# R7KA8D2AD register map
Vendor: Renesas Electronics Corporation; Series: RA8; File version: 1.10.02
CPU: CM85 r0p2, little endian, MPU, FPU, VTOR, 4 interrupt priority bits, 96 interrupts
Registers are 32-bit, read-write, reset 0x0 unless marked. A register's access mark holds for its fields unless they carry their own. Offsets are from the block's base; [hi:lo] are bit positions; {n}, {i} and the like mark numbered series; 'fields as' and 'values as' point back to an identical list.

## PORT0 — Pmn Pin FunctionPort 0 Control RegistersPmn Pin Function Control Register
Base 0x40400000
Same registers: PORT5 0x404000A0, PORT6 0x404000C0, PORT7 0x404000E0, PORT8 0x40400100, PORT9 0x40400120, PORTA 0x40400140, PORTB 0x40400160, PORTC 0x40400180, PORTD 0x404001A0, PORT0_NS 0x50400000, PORT5_NS 0x504000A0, PORT6_NS 0x504000C0, PORT7_NS 0x504000E0, PORT8_NS 0x50400100, PORT9_NS 0x50400120, PORTA_NS 0x50400140, PORTB_NS 0x50400160, PORTC_NS 0x50400180, PORTD_NS 0x504001A0
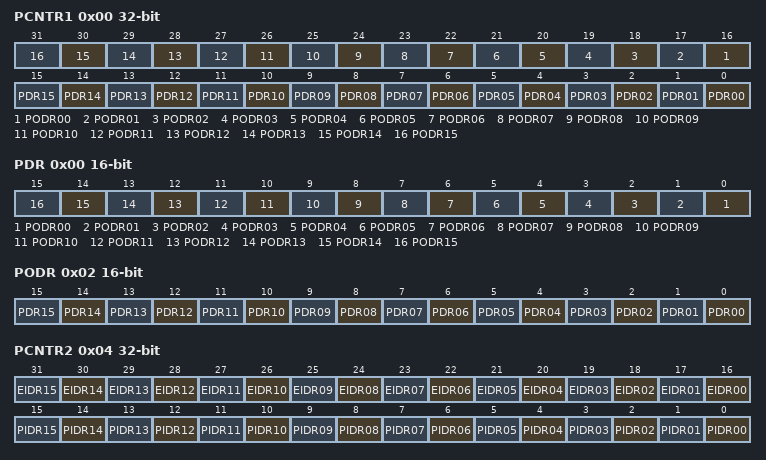
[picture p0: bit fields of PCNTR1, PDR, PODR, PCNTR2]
0x00 PCNTR1 — Port Control Register 1
  [n+16] PODR{n:02} (n=0..15) — Pmn Output Data
    0=Low output; 1=High output
  [n] PDR{n:02} (n=0..15) — Pmn Direction
    0=Input (functions as an input pin); 1=Output (functions as an output pin)
0x00 PDR 16-bit (alternate view of PCNTR1) — Port Control Register 1
  [all] fields
    0=Low output; 1=High output
  [n] PODR{n:02} (n=0..15) — Pmn Output Data
0x02 PODR 16-bit (alternate view of PCNTR1) — Port Control Register 1
  [all] fields
    values as PCNTR1.PDR00
  [n] PDR{n:02} (n=0..15) — Pmn Direction
0x04 PCNTR2 ro (reset mask 0xFFFF0000) — Port Control Register 2
  [n+16] EIDR{n:02} (n=0..15) — Port Event Input Data
    0=Low input; 1=High input
  [n] PIDR{n:02} (n=0..15) — Pmn State
    0=Low level; 1=High level
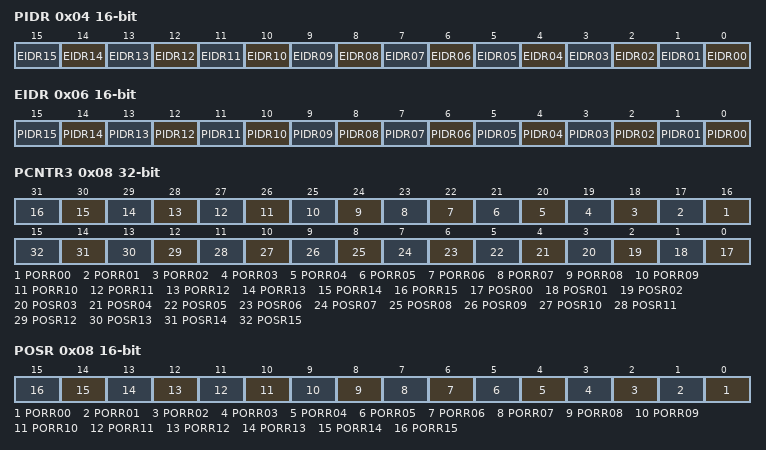
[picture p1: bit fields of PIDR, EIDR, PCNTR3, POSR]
0x04 PIDR 16-bit ro (alternate view of PCNTR2) — Port Control Register 2
  [all] fields
    0=Low input; 1=High input
  [n] EIDR{n:02} (n=0..15) — Port Event Input Data
0x06 EIDR 16-bit ro reset not defined (alternate view of PCNTR2) — Port Control Register 2
  [all] fields
    0=Low level; 1=High level
  [n] PIDR{n:02} (n=0..15) — Pmn State
0x08 PCNTR3 wo — Port Control Register 3
  [n+16] PORR{n:02} (n=0..15) — Pmn Output Reset
    0=No effect on output; 1=Low output
  [n] POSR{n:02} (n=0..15) — Pmn Output Set
    0=No effect on output; 1=High output
0x08 POSR 16-bit wo (alternate view of PCNTR3) — Port Control Register 3
  [all] fields
    0=No effect on output; 1=Low output
  [n] PORR{n:02} (n=0..15) — Pmn Output Reset
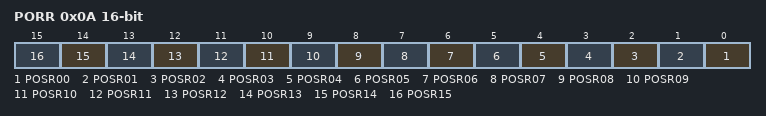
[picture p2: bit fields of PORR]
0x0A PORR 16-bit wo (alternate view of PCNTR3) — Port Control Register 3
  [all] fields
    0=No effect on output; 1=High output
  [n] POSR{n:02} (n=0..15) — Pmn Output Set

## PORT1 — Pmn Pin FunctionPort 1 Control RegistersPmn Pin Function Control Register
Base 0x40400020
Same registers: PORT2 0x40400040, PORT3 0x40400060, PORT4 0x40400080, PORT1_NS 0x50400020, PORT2_NS 0x50400040, PORT3_NS 0x50400060, PORT4_NS 0x50400080
Registers as PORT0; these are added or differ:
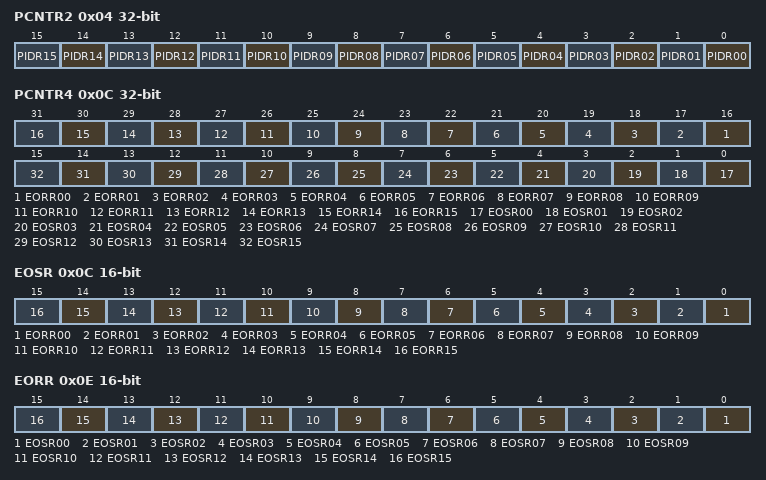
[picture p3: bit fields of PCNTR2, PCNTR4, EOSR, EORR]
0x04 PCNTR2 ro (reset mask 0xFFFF0000) — Port Control Register 2
  [all] fields
    0=Low level; 1=High level
  [n] PIDR{n:02} (n=0..15) — Pmn State
0x04 PIDR 16-bit ro (alternate view of PCNTR2) — Port Control Register 2
0x0C PCNTR4 — Port Control Register 4
  [n+16] EORR{n:02} (n=0..15) — Pmn Event Output Reset
    0=No effect on output; 1=Low output
  [n] EOSR{n:02} (n=0..15) — Pmn Event Output Set
    0=No effect on output; 1=High output
0x0C EOSR 16-bit (alternate view of PCNTR4) — Port Control Register 4
  [all] fields
    0=No effect on output; 1=Low output
  [n] EORR{n:02} (n=0..15) — Pmn Event Output Reset
0x0E EORR 16-bit (alternate view of PCNTR4) — Port Control Register 4
  [all] fields
    0=No effect on output; 1=High output
  [n] EOSR{n:02} (n=0..15) — Pmn Event Output Set

## SRAM_NS — SRAM Control
Base 0x50002000
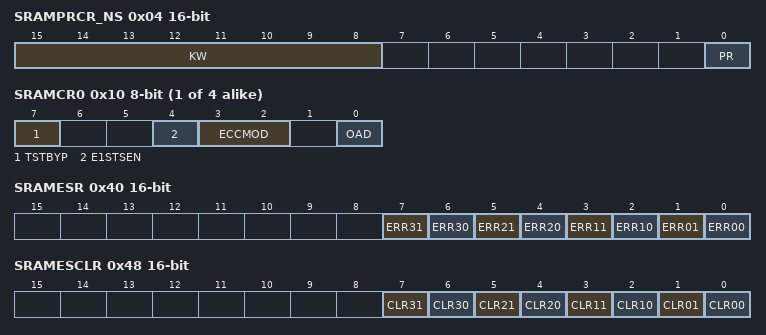
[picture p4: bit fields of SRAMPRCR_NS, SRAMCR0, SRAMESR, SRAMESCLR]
0x04 SRAMPRCR_NS 16-bit — SRAM Protection Control Register for Non-Secure
  [15:8] KW wo — Write Key Code
  [0] PR — Register Write Control
    0=Writing to registers are disabled; 1=Writing to registers are enabled
0x08 SRAMWTSC 8-bit — SRAM Wait State Control Register
  [0] WTEN — SRAM wait enable
    0=Do not add wait state in the access cycle to SRAMs; 1=Add wait state in the access cycle to SRAMs
{0x10+4i} SRAMCR{i} (i=0..3) 8-bit — SRAM Control Register {i} For ECC RAM
  [7] TSTBYP — ECC Test Enable / ECC Bypass Select
    0=Disable ECC bypass; 1=Enable ECC bypass
  [4] E1STSEN — ECC 1-bit Error Update Enable
    0=Disable updating of 1-bit ECC error; 1=Enable updating of 1-bit ECC error
  [3:2] ECCMOD — ECC Operating Mode Select
    0=Disable ECC function; 1=Setting prohibited; 2=Enable ECC function without error checking; 3=Enable ECC function with error checking
  [0] OAD — Operation after error detection
    0=Interrupt; 1=Reset
{0x30+4i} SRAMECCRGN{i} 8-bit reset 0x4 (i=0..2) — SRAM ECC Region Control Register {i}
  [2:0] ECCRGN — ECC target region select
    0=No ECC target region; 1={0x2200+8i}_0000–{0x2201+8i}_FFFF {0x3200+8i}_0000–{0x3201+8i}_FFFF (128 KB); 2={0x2200+8i}_0000–{0x2203+8i}_FFFF {0x3200+8i}_0000–{0x3203+8i}_FFFF (256 KB); 3={0x2200+8i}_0000–{0x2205+8i}_FFFF {0x3200+8i}_0000–{0x3205+8i}_FFFF (384 KB); 4={0x2200+8i}_0000–{0x2207+8i}_FFFF {0x3200+8i}_0000–{0x3207+8i}_FFFF (512 KB); other=Others (Setting prohibited)
0x3C SRAMECCRGN3 8-bit reset 0x1 — SRAM ECC Region Control Register 3
  [2:0] ECCRGN — ECC target region select
    0=No ECC target region; 1=0x2218_0000–0x2219_FFFF 0x3218_0000–0x3219_FFFF (128 KB); other=Others (Setting prohibited)
0x40 SRAMESR 16-bit ro — SRAM Error Status Register For ECC RAM
  [7] ERR31 — SRAM3 2-bit ECC Error Status
    0=2-bit ECC error has not occurred; 1=2-bit ECC error has occurred
  [6] ERR30 — SRAM3 1-bit ECC Error Status
    0=1-bit ECC error has not occurred; 1=1-bit ECC error has occurred
  [5] ERR21 — SRAM2 2-bit ECC Error Status
    values as ERR31
  [4] ERR20 — SRAM2 1-bit ECC Error Status
    values as ERR30
  [3] ERR11 — SRAM1 2-bit ECC Error Status
    values as ERR31
  [2] ERR10 — SRAM1 1-bit ECC Error Status
    values as ERR30
  [1] ERR01 — SRAM0 2-bit ECC Error Status
    values as ERR31
  [0] ERR00 — SRAM0 1-bit ECC Error Status
    values as ERR30
0x48 SRAMESCLR 16-bit wo — SRAM Error Status Clear Register For ECC RAM
  [7] CLR31 — SRAM3 2-bit ECC Error Status Clear
    0=No effect; 1=Clear 2-bit ECC error
  [6] CLR30 — SRAM3 1-bit ECC Error Status Clear
    0=No effect; 1=Clear 1-bit ECC error
  [5] CLR21 — SRAM2 2-bit ECC Error Status Clear
    0=No effect; 1=Clear 2-bit ECC error
  [4] CLR20 — SRAM2 1-bit ECC Error Status Clear
    0=No effect; 1=Clear 1-bit ECC error
  [3] CLR11 — SRAM1 2-bit ECC Error Status Clear
    0=No effect; 1=Clear 2-bit ECC error
  [2] CLR10 — SRAM1 1-bit ECC Error Status Clear
    0=No effect; 1=Clear 1-bit ECC error
  [1] CLR01 — SRAM0 2-bit ECC Error Status Clear
    0=No effect; 1=Clear 2-bit ECC error
  [0] CLR00 — SRAM0 1-bit ECC Error Status Clear
    0=No effect; 1=Clear 1-bit ECC error
{0x50+0x10*i} SRAMEAR{i}0 (i=0..3) ro — SRAM Error Address Register n0 For ECC RAM
{0x54+0x10*i} SRAMEAR{i}1 (i=0..3) ro — SRAM Error Address Register n1 For ECC RAM
